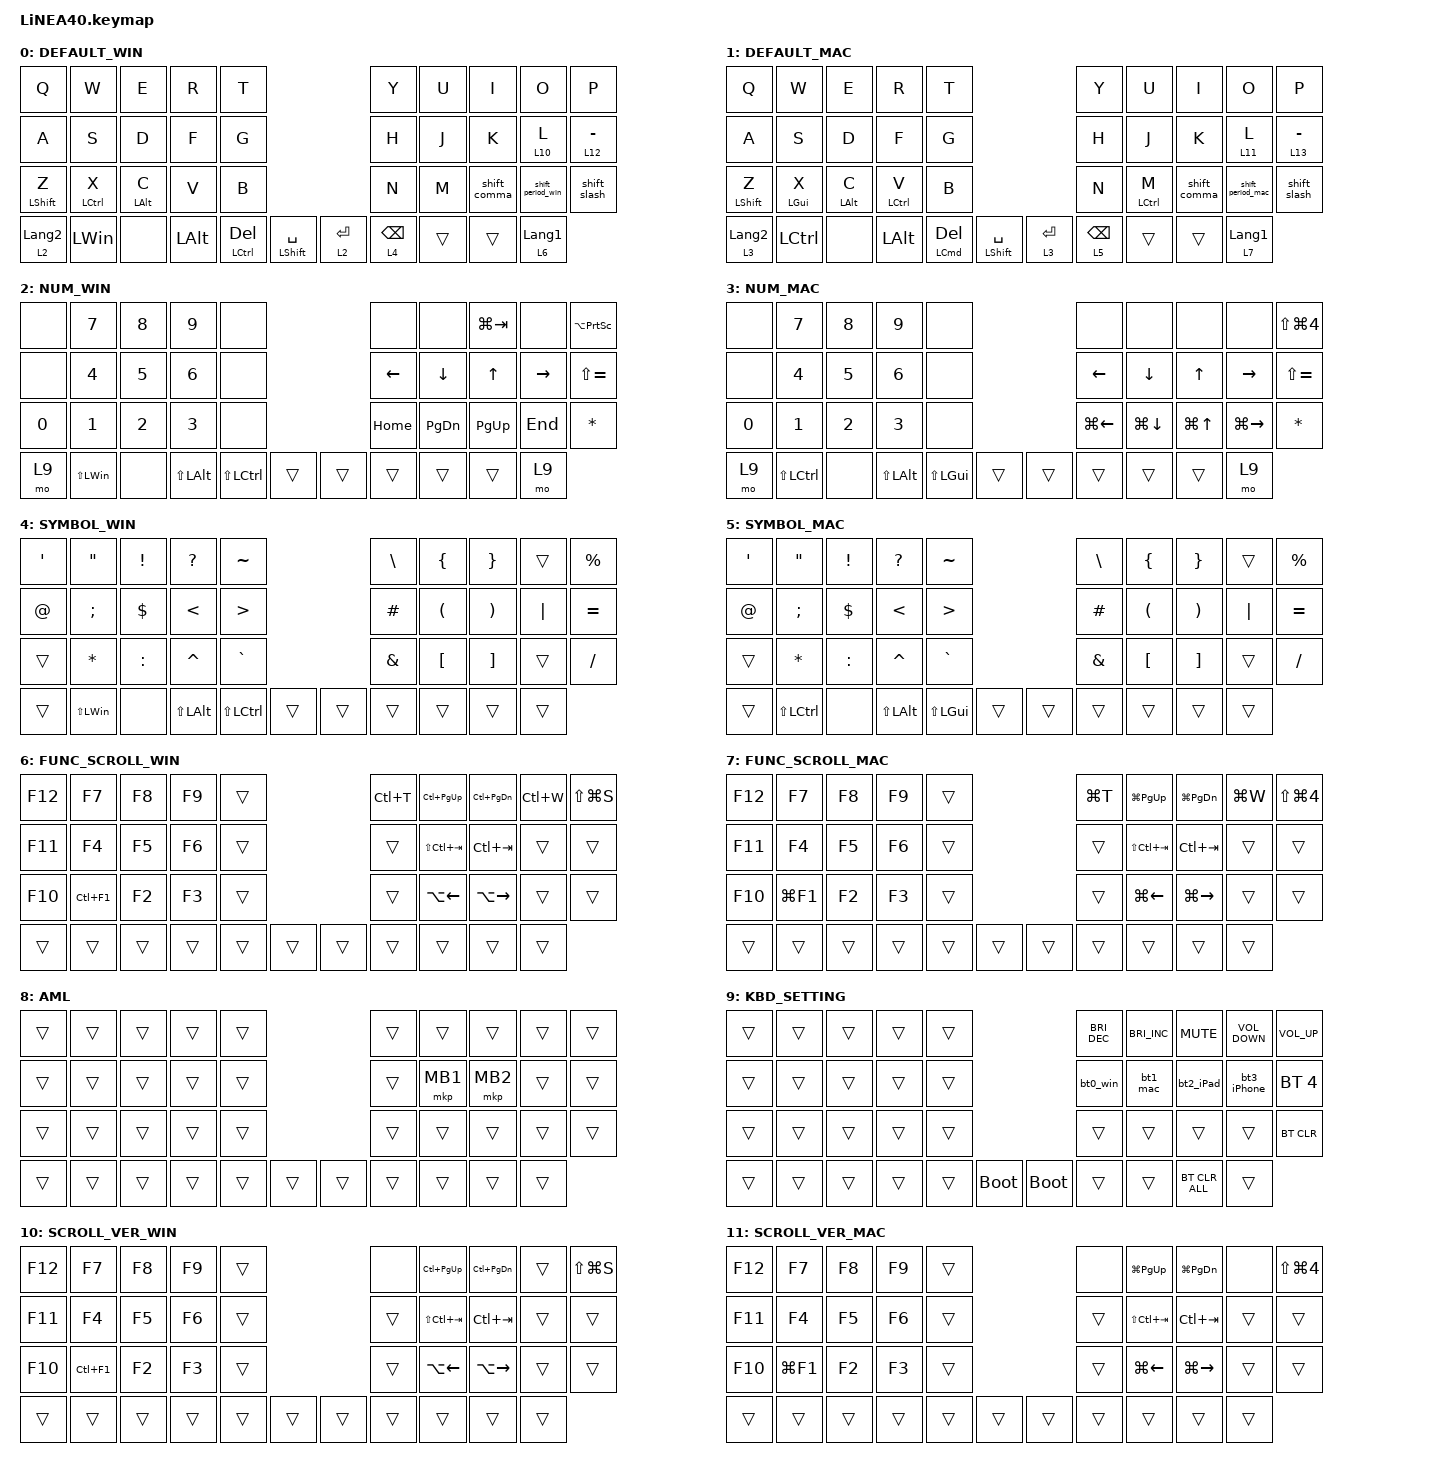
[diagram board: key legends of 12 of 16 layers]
#include <dt-bindings/zmk/input_transform.h>
#include <input/processors.dtsi>
#include <input/processors/report_rate_limit.dtsi>
#include <scroll-snap.dtsi>
#include <behaviors.dtsi>
#include <dt-bindings/zmk/bt.h>
#include <dt-bindings/zmk/keys.h>
#include <dt-bindings/zmk/pointing.h>
#include "elpekenin/behaviors.dtsi"

#define DEFAULT_WIN 0
#define DEFAULT_MAC 1
#define NUM_WIN 2
#define NUM_MAC 3
#define SYMBOL_WIN 4
#define SYMBOL_MAC 5
#define FUNC_SCROLL_WIN 6
#define FUNC_SCROLL_MAC 7
#define AML 8
#define KBD_SETTING 9
#define SCROLL_VER_WIN 10
#define SCROLL_VER_MAC 11
#define SCROLL_HOR_WIN 12
#define SCROLL_HOR_MAC 13
#define GESTURE_WIN 14
#define GESTURE_MAC 15

// ロータリーエンコーダー: スクロール量変更の定義を追記

#undef ZMK_POINTING_DEFAULT_SCRL_VAL  // 定義を削除
#define ZMK_POINTING_DEFAULT_SCRL_VAL 60

// スクロールスナップの設定

&zip_scroll_snap {
    x-threshold = <5 8>;
    y-threshold = <8 5>;
    xy-threshold = <5 8>;
    require-n-samples = <4>;
    immediate-snap-threshold = <800>;
    lock-duration-ms = <300>;
    lock-for-next-n-events = <10>;
    idle-reset-timeout-ms = <300>;
};

//マウスカーソルの挙動設定

&mmv {
    delay-ms = <20>;
    time-to-max-speed-ms = <300>;
    acceleration-exponent = <2>;
};

//マウススクロールの挙動設定

&msc {
    delay-ms = <0>;
    time-to-max-speed-ms = <500>;
    acceleration-exponent = <2>;
};

// Inpur-ProcessorによるAML設定
// クリック後、250ms後にAML解除

&mkp_input_listener { input-processors = <&zip_temp_layer AML 250>; };

&mt {
    flavor = "balanced";
    tapping-term-ms = <180>;
    quick-tap-ms = <180>;
};

&lt {
    tapping-term-ms = <180>;
    quick-tap-ms = <180>;
};

&sl { release-after-ms = <30000>; };

/ {
    // excluded-positionsの設定

    /omit-if-no-ref/

    zip_temp_layer: zip_temp_layer {
        compatible = "zmk,input-processor-temp-layer";
        #input-processor-cells = <2>;

        // 以下で指定したキー以外を押すとAML解除

        excluded-positions = <
            16 // J
            17 // K
            18 // L
            27 // ,
            28 // .
            36 // BACKSPACE
            37 // SPACE
        >;

        // キー入力から300ms間はAMLを発動しない

        require-prior-idle-ms = <300>;
    };

    // Threshold付きAML: トラックボールを一定以上動かしたときにAMLを発動

    zip_temp_layer_threshold: zip_temp_layer_threshold {
        compatible = "zmk,input-processor-temp-layer-threshold";
        #input-processor-cells = <2>;

        // AML発動に必要な累積移動量

        threshold = <15>;

        // 以下で指定したキー以外を押すとAML解除

        excluded-positions = <
            16 // J
            17 // K
            18 // L
            28 // ,
            29 // .
            36 // BACKSPACE
            37 // SPACE
        >;

        // キー入力から300ms間はAMLを発動しない

        require-prior-idle-ms = <0>;

        // 蓄積された移動量をリセットするまでの時間

        reset-timeout-ms = <200>;
    };

    // トラックボール入力をキー入力に変換

    zip_arrow_keys: zip_arrow_keys {
        compatible = "zmk,input-processor-keybind";
        #input-processor-cells = <0>;
        track_remainders;
        bindings = <&kp RIGHT>, <&kp LEFT>, <&kp UP>, <&kp DOWN>;

        tick = <10>;
        wait-ms = <5>;
        tap-ms = <5>;
        mode = <1>;
    };

    // トラックボール入力を音量・輝度操作に変換

    zip_volume_keys: zip_volume_keys {
        compatible = "zmk,input-processor-keybind";
        #input-processor-cells = <0>;
        track_remainders;
        bindings =
            <&kp C_VOLUME_UP>,
            <&kp C_VOLUME_DOWN>,
            <&kp C_BRIGHTNESS_INC>,
            <&kp C_BRIGHTNESS_DEC>;

        tick = <10>;
        wait-ms = <5>;
        tap-ms = <5>;
        mode = <1>;
    };

    trackball_listener {
        status = "okay";
        compatible = "zmk,input-listener";
        device = <&trackball>;

        // レポートレート制限 + Threshold付きAML (15ピクセル以上動かすとAML発動、30秒後に解除)

        input-processors =
            <&zip_report_rate_limit 16>,
            <&zip_temp_layer_threshold AML 30000>;

        // 自由スクロール
        // Macの場合

        scroller_mac {
            layers = <FUNC_SCROLL_MAC>;
            input-processors =
                <&zip_xy_scaler 1 16>,
                <&zip_xy_transform INPUT_TRANSFORM_Y_INVERT>,
                <&zip_xy_to_scroll_mapper>;
        };

        // Windowsの場合

        scroller_win {
            layers = <FUNC_SCROLL_WIN>;
            input-processors =
                <&zip_xy_scaler 1 8>,
                <&zip_xy_transform INPUT_TRANSFORM_X_INVERT>,
                <&zip_xy_to_scroll_mapper>;
        };

        // 縦横別のスクロール
        // Mac

        scroller_mac_vertical {
            layers = <SCROLL_VER_MAC>;
            input-processors =
                <&zip_y_scaler 1 16>,
                <&zip_x_scaler 0 1>,
                <&zip_xy_transform INPUT_TRANSFORM_Y_INVERT>,
                <&zip_xy_to_scroll_mapper>;
        };

        // 横スクロール

        scroller_mac_horizontal {
            layers = <SCROLL_HOR_MAC>;
            input-processors =
                <&zip_x_scaler 1 16>,
                <&zip_y_scaler 0 1>,
                <&zip_xy_to_scroll_mapper>;
        };

        // Windows

        scroller_win_vertical {
            layers = <SCROLL_VER_WIN>;
            input-processors =
                <&zip_y_scaler 1 12>,
                <&zip_x_scaler 0 1>,
                <&zip_xy_to_scroll_mapper>;
        };

        // 横スクロール

        scroller_win_horizontal {
            layers = <SCROLL_HOR_WIN>;
            input-processors =
                <&zip_x_scaler 1 12>,
                <&zip_y_scaler 0 1>,
                <&zip_xy_transform INPUT_TRANSFORM_X_INVERT>,
                <&zip_xy_to_scroll_mapper>;
        };

        // トラックボール入力→キー入力

        arrow_keys {
            layers = <NUM_WIN NUM_MAC>;
            input-processors = <&zip_arrow_keys>;
            process-next;
        };

        // レイヤー9 (KBD_SETTING) で直交移動のみ有効にして音量・輝度調整
        // トラックボールの動きをX軸またはY軸のみにスナップしてからキー入力に変換

        volume_keys {
            layers = <KBD_SETTING>;
            input-processors = <&zip_cursor_snap>, <&zip_volume_keys>;

            process-next;
        };

        // カーソルの動きをゼロにする

        post_volume_keys {
            layers = <NUM_WIN NUM_MAC KBD_SETTING>;
            input-processors = <&zip_xy_scaler 0 1>;
        };
    };
};

/ {
    combos {
        compatible = "zmk,combos";

        tab {
            bindings = <&kp TAB>;
            key-positions = <11 12>;
            timeout-ms = <80>;
        };

        shift_tab {
            bindings = <&kp LS(TAB)>;
            key-positions = <12 13>;
            timeout-ms = <80>;
        };

        Esc {
            bindings = <&kp ESCAPE>;
            key-positions = <0 1>;
            timeout-ms = <80>;
        };

        middle_click {
            bindings = <&mkp MB3>;
            key-positions = <16 17>;
            timeout-ms = <80>;
        };
    };

    macros {
        to_layer_0: to_layer_0 {
            compatible = "zmk,behavior-macro-one-param";
            #binding-cells = <1>;
            bindings = <&to 0 &macro_param_1to1 &kp MACRO_PLACEHOLDER>;
            label = "TO_LAYER_0";
        };

        bt0_win: bt0 {
            compatible = "zmk,behavior-macro";
            #binding-cells = <0>;
            bindings =
                <&bt BT_SEL 0 &bt BT_DISC 1 &bt BT_DISC 2 &bt BT_DISC 3 &bt BT_DISC 4>,
                <&macro_wait_time 200>,
                <&df 0>;

            label = "BT0";
        };

        bt1_mac: bt1 {
            compatible = "zmk,behavior-macro";
            #binding-cells = <0>;
            bindings =
                <&bt BT_SEL 1 &bt BT_DISC 0 &bt BT_DISC 2 &bt BT_DISC 3 &bt BT_DISC 4>,
                <&macro_wait_time 200>,
                <&df 1>;

            label = "BT1";
        };

        bt2_iPad: bt2_iPad {
            compatible = "zmk,behavior-macro";
            #binding-cells = <0>;
            bindings =
                <&bt BT_SEL 2 &bt BT_DISC 0 &bt BT_DISC 1 &bt BT_DISC 3 &bt BT_DISC 4>,
                <&macro_wait_time 200>,
                <&df 1>;

            label = "BT2_IPAD";
        };

        bt3_iPhone: bt3_iPhone {
            compatible = "zmk,behavior-macro";
            #binding-cells = <0>;
            bindings =
                <&bt BT_SEL 3 &bt BT_DISC 0 &bt BT_DISC 1 &bt BT_DISC 2 &bt BT_DISC 4>,
                <&macro_wait_time 200>,
                <&df 1>;

            label = "BT3_IPHONE";
        };

        // AML起動中にスクロールレイヤに入るためのマクロ(zaruSaruさん実装)

        to_scroll_layer_win: to_scroll_layer_win {
            compatible = "zmk,behavior-macro";
            #binding-cells = <0>;
            bindings =
                <&to FUNC_SCROLL_WIN>,
                <&macro_press>,
                <&mo FUNC_SCROLL_WIN>,
                <&macro_pause_for_release>,
                <&macro_release>,
                <&mo FUNC_SCROLL_WIN>;

            label = "TO_SCROLL_LAYER_WIN";
        };

        to_scroll_layer_mac: to_scroll_layer_mac {
            compatible = "zmk,behavior-macro";
            #binding-cells = <0>;
            bindings =
                <&to FUNC_SCROLL_MAC>,
                <&macro_press>,
                <&mo FUNC_SCROLL_MAC>,
                <&macro_pause_for_release>,
                <&macro_release>,
                <&mo FUNC_SCROLL_MAC>;

            label = "TO_SCROLL_LAYER_MAC";
        };

        // タップ時のみAML解除するための設定

        exit_AML: exit_AML {
            compatible = "zmk,behavior-macro";
            wait-ms = <0>;
            tap-ms = <0>;
            #binding-cells = <0>;
            bindings = <&tog_off AML>;
            label = "exit_AML";
        };

        kp_exit_AML: kp_exit_AML {
            compatible = "zmk,behavior-macro-one-param";
            wait-ms = <0>;
            tap-ms = <0>;
            #binding-cells = <1>;
            bindings = <&macro_param_1to1 &kp MACRO_PLACEHOLDER &exit_AML>;
            label = "KP_exit_AML";
        };

        move_window_left_max: move_window_left_max {
            compatible = "zmk,behavior-macro";
            #binding-cells = <0>;
            bindings =
                <&kp LG(LEFT)>,
                <&macro_wait_time 20>,
                <&kp LG(RIGHT)>,
                <&macro_wait_time 20>,
                <&kp LS(LG(LEFT))>,
                <&macro_wait_time 50>,
                <&kp LG(UP_ARROW)>;

            label = "MOVE_WINDOW_LEFT_MAX";
        };

        move_window_right_max: move_window_right_max {
            compatible = "zmk,behavior-macro";
            #binding-cells = <0>;
            bindings =
                <&kp LG(LEFT)>,
                <&macro_wait_time 20>,
                <&kp LG(RIGHT)>,
                <&macro_wait_time 20>,
                <&kp LS(LG(RIGHT))>,
                <&macro_wait_time 50>,
                <&kp LG(UP_ARROW)>;

            label = "MOVE_WINDOW_RIGHT_MAX";
        };
    };

    behaviors {
        lt_to_layer_0: lt_to_layer_0 {
            compatible = "zmk,behavior-hold-tap";
            label = "LAYER_TAP_TO_0";
            bindings = <&mo>, <&to_layer_0>;

            #binding-cells = <2>;
            tapping-term-ms = <200>;
        };

        // タップ時のみAML解除するための設定

        mt_exit_AML_on_tap: mt_exit_AML_on_tap {
            compatible = "zmk,behavior-hold-tap";
            label = "MT_exit_AML_ON_TAP";
            bindings = <&kp>, <&kp_exit_AML>;

            #binding-cells = <2>;
            tapping-term-ms = <200>;
            flavor = "tap-preferred";
            quick-tap-ms = <100>;
        };

        // ロータリーエンコーダーでスクロールする設定
        // mac用

        encoder_msc_down_up: encoder_msc_down_up {
            compatible = "zmk,behavior-sensor-rotate";
            label = "ENCODER_MSC_DOWN_UP";
            #sensor-binding-cells = <0>;
            bindings = <&msc SCRL_DOWN>, <&msc SCRL_UP>;

            tap-ms = <20>;
        };

        encoder_msc_right_left: encoder_msc_right_left {
            compatible = "zmk,behavior-sensor-rotate";
            label = "ENCODER_MSC_RIGHT_LEFT";
            #sensor-binding-cells = <0>;
            bindings = <&msc SCRL_RIGHT>, <&msc SCRL_LEFT>;

            tap-ms = <20>;
        };

        // windows用

        encoder_msc_up_down: encoder_msc_up_down {
            compatible = "zmk,behavior-sensor-rotate";
            label = "ENCODER_MSC_UP_DOWN";
            #sensor-binding-cells = <0>;
            bindings = <&msc SCRL_UP>, <&msc SCRL_DOWN>;

            tap-ms = <20>;
        };

        encoder_msc_left_right: encoder_msc_left_right {
            compatible = "zmk,behavior-sensor-rotate";
            label = "ENCODER_MSC_LEFT_RIGHT";
            #sensor-binding-cells = <0>;
            bindings = <&msc SCRL_LEFT>, <&msc SCRL_RIGHT>;

            tap-ms = <20>;
        };

        // 接続先に応じてデフォルトレイヤーを変更するための動作

        tog_on: toggle_layer_on_only {
            compatible = "zmk,behavior-toggle-layer";
            #binding-cells = <1>;
            display-name = "Toggle Layer On";
            toggle-mode = "on";
        };

        tog_off: toggle_layer_off_only {
            compatible = "zmk,behavior-toggle-layer";
            #binding-cells = <1>;
            display-name = "Toggle Layer Off";
            toggle-mode = "off";
        };

        // リピート付きのSpace and Shift

        sands: space_and_shift {
            compatible = "zmk,behavior-hold-tap";
            label = "SPACE_AND_SHIFT";
            #binding-cells = <2>;
            flavor = "tap-unless-interrupted";
            tapping-term-ms = <220>;
            quick-tap-ms = <125>;
            global-quick-tap;
            bindings = <&kp>, <&kp>;
        };

        // mod morphによるKey Overrideの再現
        // Shift+, -> !
        // shift+. -> ?

        shift_comma: shift_comma {
            compatible = "zmk,behavior-mod-morph";
            #binding-cells = <0>;
            bindings = <&mt LEFT_ALT COMMA>, <&kp EXCLAMATION>;

            mods = <(MOD_LSFT|MOD_RSFT)>;
        };

        shift_period_win: shift_period_win {
            compatible = "zmk,behavior-mod-morph";
            #binding-cells = <0>;
            bindings = <&mt LCTRL PERIOD>, <&kp QUESTION>;

            mods = <(MOD_LSFT|MOD_RSFT)>;
        };

        shift_period_mac: shift_period_mac {
            compatible = "zmk,behavior-mod-morph";
            #binding-cells = <0>;
            bindings = <&mt LEFT_GUI DOT>, <&kp QUESTION>;

            mods = <(MOD_LSFT|MOD_RSFT)>;
        };

        shift_slash: shift_slash {
            compatible = "zmk,behavior-mod-morph";
            #binding-cells = <0>;
            bindings = <&mt LEFT_SHIFT SLASH>, <&kp BACKSLASH>;

            mods = <(MOD_LSFT|MOD_RSFT)>;
            label = "SHIFT_SLASH";
        };

        TD_0_win: TD_0_win {
            compatible = "zmk,behavior-tap-dance";
            label = "TD_0_WIN";
            #binding-cells = <0>;
            bindings = <&lt 10 MINUS>, <&lt 12 LS(EQUAL)>;

            tapping-term-ms = <170>;
        };

        TD_0_mac: TD_0_mac {
            compatible = "zmk,behavior-tap-dance";
            label = "TD_0_MAC";
            #binding-cells = <0>;
            bindings = <&lt 11 MINUS>, <&lt 13 LS(EQUAL)>;

            tapping-term-ms = <170>;
        };

        lt_tap_pref: lt_tap_pref {
            compatible = "zmk,behavior-hold-tap";
            label = "LT_TAP_PREF";
            bindings = <&mo>, <&kp>;

            #binding-cells = <2>;
            tapping-term-ms = <180>;
            quick-tap-ms = <180>;
            flavor = "tap-preferred";
        };
    };

    keymap {
        compatible = "zmk,keymap";

        DEFAULT_WIN {
            bindings = <
&kp Q             &kp W         &kp E           &kp R         &kp T                                                  &kp Y            &kp U  &kp I         &kp O              &kp P
&kp A             &kp S         &kp D           &kp F         &kp G                                                  &kp H            &kp J  &kp K         &lt 10 L           &lt 12 MINUS
&mt LEFT_SHIFT Z  &mt LCTRL X   &mt LEFT_ALT C  &kp V         &kp B                                                  &kp N            &kp M  &shift_comma  &shift_period_win  &shift_slash
&lt 2 LANGUAGE_2  &kp LEFT_WIN  &none           &kp LEFT_ALT  &mt LCTRL DELETE  &mt LEFT_SHIFT SPACE    &lt 2 ENTER  &lt 4 BACKSPACE         &trans        &trans             &lt 6 LANGUAGE_1
            >;

            sensor-bindings = <&encoder_msc_up_down>;
        };

        DEFAULT_MAC {
            bindings = <
&kp Q             &kp W             &kp E           &kp R               &kp T                                                         &kp Y            &kp U               &kp I         &kp O              &kp P
&kp A             &kp S             &kp D           &kp F               &kp G                                                         &kp H            &kp J               &kp K         &lt 11 L           &lt 13 MINUS
&mt LEFT_SHIFT Z  &mt LEFT_GUI X    &mt LEFT_ALT C  &mt LEFT_CONTROL V  &kp B                                                         &kp N            &mt LEFT_CONTROL M  &shift_comma  &shift_period_mac  &shift_slash
&lt 3 LANGUAGE_2  &kp LEFT_CONTROL  &none           &kp LEFT_ALT        &mt LEFT_COMMAND DELETE  &mt LEFT_SHIFT SPACE    &lt 3 ENTER  &lt 5 BACKSPACE                      &trans        &trans             &lt 7 LANGUAGE_1
            >;

            sensor-bindings = <&encoder_msc_down_up>;
        };

        NUM_WIN {
            bindings = <
&none         &kp NUMBER_7      &kp NUMBER_8  &kp NUMBER_9      &none                                   &none     &none          &kp LG(TAB)  &none      &kp LA(PRINTSCREEN)
&none         &kp NUMBER_4      &kp NUMBER_5  &kp NUMBER_6      &none                                   &kp LEFT  &kp DOWN       &kp UP       &kp RIGHT  &kp LS(EQUAL)
&kp NUMBER_0  &kp NUMBER_1      &kp NUMBER_2  &kp NUMBER_3      &none                                   &kp HOME  &kp PAGE_DOWN  &kp PAGE_UP  &kp END    &kp ASTERISK
&mo 9         &kp LS(LEFT_WIN)  &none         &kp LS(LEFT_ALT)  &kp LS(LEFT_CONTROL)  &trans    &trans  &trans                   &trans       &trans     &mo 9
            >;

            sensor-bindings = <&encoder_msc_up_down>;
        };

        NUM_MAC {
            bindings = <
&none   &kp N7                &kp N8  &kp N9            &none                               &none         &none         &none       &none          &kp LS(LG(NUMBER_4))
&none   &kp N4                &kp N5  &kp N6            &none                               &kp LEFT      &kp DOWN      &kp UP      &kp RIGHT      &kp LS(EQUAL)
&kp N0  &kp N1                &kp N2  &kp N3            &none                               &kp LG(LEFT)  &kp LG(DOWN)  &kp LG(UP)  &kp LG(RIGHT)  &kp ASTERISK
&mo 9   &kp LS(LEFT_CONTROL)  &none   &kp LS(LEFT_ALT)  &kp LS(LEFT_GUI)  &trans    &trans  &trans                      &trans      &trans         &mo 9
            >;

            sensor-bindings = <&inc_dec_kp LEFT RIGHT>;
        };

        SYMBOL_WIN {
            bindings = <
&kp SQT      &kp DOUBLE_QUOTES  &kp EXCLAMATION  &kp QUESTION      &kp TILDE                           &kp BACKSLASH  &kp LEFT_BRACE        &kp RIGHT_BRACE        &trans    &kp PERCENT
&kp AT_SIGN  &kp SEMICOLON      &kp DOLLAR       &kp LESS_THAN     &kp GREATER_THAN                    &kp HASH       &kp LEFT_PARENTHESIS  &kp RIGHT_PARENTHESIS  &kp PIPE  &kp EQUAL
&trans       &kp ASTERISK       &kp COLON        &kp CARET         &kp GRAVE                           &kp AMPERSAND  &kp LEFT_BRACKET      &kp RIGHT_BRACKET      &trans    &kp SLASH
&trans       &kp LS(LEFT_WIN)   &none            &kp LS(LEFT_ALT)  &kp LS(LCTRL)     &trans    &trans  &trans                               &trans                 &trans    &trans
            >;

            sensor-bindings = <&encoder_msc_up_down>;
        };

        SYMBOL_MAC {
            bindings = <
&kp SQT      &kp DOUBLE_QUOTES     &kp EXCLAMATION  &kp QUESTION      &kp TILDE                           &kp BACKSLASH  &kp LEFT_BRACE        &kp RIGHT_BRACE        &trans    &kp PERCENT
&kp AT_SIGN  &kp SEMICOLON         &kp DOLLAR       &kp LESS_THAN     &kp GREATER_THAN                    &kp HASH       &kp LEFT_PARENTHESIS  &kp RIGHT_PARENTHESIS  &kp PIPE  &kp EQUAL
&trans       &kp ASTERISK          &kp COLON        &kp CARET         &kp GRAVE                           &kp AMPERSAND  &kp LEFT_BRACKET      &kp RIGHT_BRACKET      &trans    &kp SLASH
&trans       &kp LS(LEFT_CONTROL)  &none            &kp LS(LEFT_ALT)  &kp LS(LEFT_GUI)  &trans    &trans  &trans                               &trans                 &trans    &trans
            >;

            sensor-bindings = <&inc_dec_kp C_VOLUME_DOWN C_VOLUME_UP>;
        };

        FUNC_SCROLL_WIN {
            bindings = <
&kp F12  &kp F7      &kp F8  &kp F9  &trans                    &kp LC(T)  &kp LC(PAGE_UP)  &kp LC(PAGE_DOWN)  &kp LC(W)  &kp LS(LG(S))
&kp F11  &kp F4      &kp F5  &kp F6  &trans                    &trans     &kp LS(LC(TAB))  &kp LC(TAB)        &trans     &trans
&kp F10  &kp LC(F1)  &kp F2  &kp F3  &trans                    &trans     &kp LA(LEFT)     &kp LA(RIGHT)      &trans     &trans
&trans   &trans      &trans  &trans  &trans  &trans    &trans  &trans                      &trans             &trans     &trans
            >;

            sensor-bindings = <&encoder_msc_up_down>;
        };

        FUNC_SCROLL_MAC {
            bindings = <
&kp F12  &kp F7      &kp F8  &kp F9  &trans                    &kp LG(T)  &kp LG(PAGE_UP)  &kp LG(PAGE_DOWN)  &kp LG(W)  &kp LS(LG(NUMBER_4))
&kp F11  &kp F4      &kp F5  &kp F6  &trans                    &trans     &kp LS(LC(TAB))  &kp LC(TAB)        &trans     &trans
&kp F10  &kp LG(F1)  &kp F2  &kp F3  &trans                    &trans     &kp LG(LEFT)     &kp LG(RIGHT)      &trans     &trans
&trans   &trans      &trans  &trans  &trans  &trans    &trans  &trans                      &trans             &trans     &trans
            >;

            sensor-bindings = <&inc_dec_kp LG(PLUS) LG(MINUS)>;
        };

        AML {
            bindings = <
&trans  &trans  &trans  &trans  &trans                    &trans  &trans    &trans    &trans  &trans
&trans  &trans  &trans  &trans  &trans                    &trans  &mkp MB1  &mkp MB2  &trans  &trans
&trans  &trans  &trans  &trans  &trans                    &trans  &trans    &trans    &trans  &trans
&trans  &trans  &trans  &trans  &trans  &trans    &trans  &trans            &trans    &trans  &trans
            >;
        };

        KBD_SETTING {
            bindings = <
&trans  &trans  &trans  &trans  &trans                              &kp C_BRIGHTNESS_DEC  &kp C_BRIGHTNESS_INC  &kp K_MUTE  &kp C_VOLUME_DOWN  &kp C_VOLUME_UP
&trans  &trans  &trans  &trans  &trans                              &bt0_win              &bt1_mac              &bt2_iPad   &bt3_iPhone        &bt BT_SEL 4
&trans  &trans  &trans  &trans  &trans                              &trans                &trans                &trans      &trans             &bt BT_CLR
&trans  &trans  &trans  &trans  &trans  &bootloader    &bootloader  &trans                                      &trans      &bt BT_CLR_ALL     &trans
            >;
        };

        SCROLL_VER_WIN {
            bindings = <
&kp F12  &kp F7      &kp F8  &kp F9  &trans                    &none   &kp LC(PAGE_UP)  &kp LC(PAGE_DOWN)  &trans  &kp LS(LG(S))
&kp F11  &kp F4      &kp F5  &kp F6  &trans                    &trans  &kp LS(LC(TAB))  &kp LC(TAB)        &trans  &trans
&kp F10  &kp LC(F1)  &kp F2  &kp F3  &trans                    &trans  &kp LA(LEFT)     &kp LA(RIGHT)      &trans  &trans
&trans   &trans      &trans  &trans  &trans  &trans    &trans  &trans                   &trans             &trans  &trans
            >;
        };

        SCROLL_VER_MAC {
            bindings = <
&kp F12  &kp F7      &kp F8  &kp F9  &trans                    &none   &kp LG(PAGE_UP)  &kp LG(PAGE_DOWN)  &none   &kp LS(LG(NUMBER_4))
&kp F11  &kp F4      &kp F5  &kp F6  &trans                    &trans  &kp LS(LC(TAB))  &kp LC(TAB)        &trans  &trans
&kp F10  &kp LG(F1)  &kp F2  &kp F3  &trans                    &trans  &kp LG(LEFT)     &kp LG(RIGHT)      &trans  &trans
&trans   &trans      &trans  &trans  &trans  &trans    &trans  &trans                   &trans             &trans  &trans
            >;
        };

        SCROLL_HOR_WIN {
            bindings = <
&kp F12  &kp F7      &kp F8  &kp F9  &trans                    &none   &kp LC(PAGE_UP)  &kp LC(PAGE_DOWN)  &trans  &kp LS(LG(S))
&kp F11  &kp F4      &kp F5  &kp F6  &trans                    &trans  &kp LS(LC(TAB))  &kp LC(TAB)        &trans  &trans
&kp F10  &kp LC(F1)  &kp F2  &kp F3  &trans                    &trans  &kp LA(LEFT)     &kp LA(RIGHT)      &trans  &trans
&trans   &trans      &trans  &trans  &trans  &trans    &trans  &trans                   &trans             &trans  &trans
            >;
        };

        SCROLL_HOR_MAC {
            bindings = <
&kp F12  &kp F7      &kp F8  &kp F9  &trans                    &none   &kp LG(PAGE_UP)  &kp LG(PAGE_DOWN)  &none   &kp LS(LG(NUMBER_4))
&kp F11  &kp F4      &kp F5  &kp F6  &trans                    &trans  &kp LS(LC(TAB))  &kp LC(TAB)        &trans  &trans
&kp F10  &kp LG(F1)  &kp F2  &kp F3  &trans                    &trans  &kp LG(LEFT)     &kp LG(RIGHT)      &trans  &trans
&trans   &trans      &trans  &trans  &trans  &trans    &trans  &trans                   &trans             &trans  &trans
            >;
        };

        GESTURE_WIN {
            bindings = <
&trans  &trans  &trans  &trans  &trans                    &trans  &trans  &trans  &trans  &trans
&trans  &trans  &trans  &trans  &trans                    &trans  &trans  &trans  &trans  &trans
&trans  &trans  &trans  &trans  &trans                    &trans  &trans  &trans  &trans  &trans
&trans  &trans  &trans  &trans  &trans  &trans    &trans  &trans          &trans  &trans  &trans
            >;
        };

        GESTURE_MAC {
            bindings = <
&trans  &trans  &trans  &trans  &trans                    &trans  &trans  &trans  &trans  &trans
&trans  &trans  &trans  &trans  &trans                    &trans  &trans  &trans  &trans  &trans
&trans  &trans  &trans  &trans  &trans                    &trans  &trans  &trans  &trans  &trans
&trans  &trans  &trans  &trans  &trans  &trans    &trans  &trans          &trans  &trans  &trans
            >;
        };
    };

    conditional_layers {
        compatible = "zmk,conditional-layers";

        Gesture_win {
            if-layers = <10 12>;
            then-layer = <14>;
        };

        Gesture_mac {
            if-layers = <11 13>;
            then-layer = <15>;
        };
    };
};
